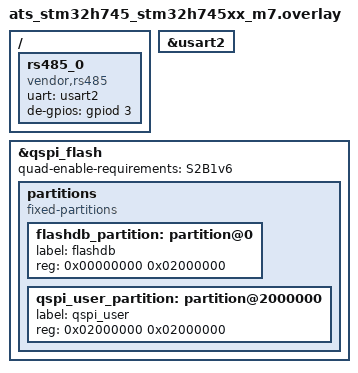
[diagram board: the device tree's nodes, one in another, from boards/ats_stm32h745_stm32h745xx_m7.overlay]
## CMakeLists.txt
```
#-------------------------------------------------------------------------------
# Zephyr Example Application
#
# Copyright (c) 2021 Nordic Semiconductor ASA
# SPDX-License-Identifier: Apache-2.0

cmake_minimum_required(VERSION 3.13.1)
find_package(Zephyr REQUIRED HINTS $ENV{ZEPHYR_BASE})

project(app LANGUAGES C)

target_include_directories(app PRIVATE
                src
                ../lib/FlashDB/inc)

target_sources(app PRIVATE
                src/main.c
                src/modbus_service.c
                src/usart_service.c
                src/modbus_points_db.c
                src/flashdb_port_zephyr.c
                src/fal_stub_zephyr.c
                ../lib/FlashDB/src/fdb.c
                ../lib/FlashDB/src/fdb_utils.c
                ../lib/FlashDB/src/fdb_kvdb.c)

# The code below locates the git index file for this repository and adds it as a dependency for
# the application VERSION file so that if the repo has a new commit added, even if no files in
# the build have changed, the application version file will be regenerated with the new git commit
find_package(Git QUIET)
if(GIT_FOUND)
  execute_process(
    COMMAND ${GIT_EXECUTABLE} rev-parse --absolute-git-dir
    WORKING_DIRECTORY .
    OUTPUT_VARIABLE application_git_dir
    OUTPUT_STRIP_TRAILING_WHITESPACE
    ERROR_STRIP_TRAILING_WHITESPACE
    ERROR_VARIABLE stderr
    RESULT_VARIABLE return_code
  )
  # If there is an error e.g. it is not a git repo, we just silently ignore it and continue
  # without a dependency, this will be the case with freestanding applications.
  if(NOT return_code)
    if(NOT "${stderr}" STREQUAL "")
      message(WARNING "Application build version git rev-parse warned: ${stderr}")
    endif()

    set_property(TARGET app_version_h PROPERTY APP_VERSION_DEPENDS ${application_git_dir}/index)
  endif()
endif()
```

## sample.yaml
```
# This file is provided so that the application can be compiled using Twister,
# the Zephyr testing tool. In this file, multiple combinations can be specified,
# so that you can easily test all of them locally or in CI.
sample:
  description: Example application
  name: example-application 
common:
  build_only: true
  integration_platforms:
    - ats_stm32h745
tests:
  app.default: {}
  app.debug:
    extra_overlay_confs:
      - debug.conf
```

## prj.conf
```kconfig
# Copyright (c) 2021 Nordic Semiconductor ASA
# SPDX-License-Identifier: Apache-2.0

# -------------------- Common --------------------
CONFIG_GPIO=y
CONFIG_SERIAL=y
CONFIG_PRINTK=y
CONFIG_LOG=y

# Enable debug during sleep/stop/standby modes
CONFIG_STM32_ENABLE_DEBUG_SLEEP_STOP=y

# -------------------- Flash / QSPI partition (for FlashDB port) --------------------
CONFIG_FLASH=y
CONFIG_FLASH_PAGE_LAYOUT=y
CONFIG_FLASH_MAP=y
CONFIG_FLASH_JESD216_API=y
CONFIG_FLASH_EX_OP_ENABLED=y
CONFIG_FLASH_STM32_QSPI_GENERIC_READ=y

# -------------------- Modbus (official Zephyr subsystem) --------------------
CONFIG_DMA=y
CONFIG_DMA_STM32=y
CONFIG_UART_ASYNC_API=y
CONFIG_UART_LINE_CTRL=n
CONFIG_NOCACHE_MEMORY=y
CONFIG_MODBUS=y
CONFIG_MODBUS_ROLE_SERVER=y
CONFIG_MODBUS_RAW_ADU=y
CONFIG_MODBUS_NUMOF_RAW_ADU=1

# Optional tuning
CONFIG_MAIN_STACK_SIZE=4096
```

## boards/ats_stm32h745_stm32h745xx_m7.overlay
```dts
/*
 * ATS-M7 app overlay
 * - Application-managed RS485 backend on USART2
 * - QSPI fixed partitions: first half reserved for FlashDB
 */

&usart2 {
	status = "okay";
};

/ {
	rs485_0: rs485_0 {
		compatible = "vendor,rs485";
		status = "okay";
		uart = <&usart2>;
		/* Adjust this pin to your actual RS485 DE wiring if different. */
		de-gpios = <&gpiod 3 GPIO_ACTIVE_HIGH>;
	};
};

&qspi_flash {
	/* Override SFDP QER value (7 unsupported by stm32-qspi driver path). */
	quad-enable-requirements = "S2B1v6";

	partitions {
		compatible = "fixed-partitions";
		#address-cells = <1>;
		#size-cells = <1>;

		/* 64MiB external flash first half for FlashDB */
		flashdb_partition: partition@0 {
			label = "flashdb";
			reg = <0x00000000 0x02000000>;
		};

		/* Remaining second half for future data/filesystem */
		qspi_user_partition: partition@2000000 {
			label = "qspi_user";
			reg = <0x02000000 0x02000000>;
		};
	};
};
```

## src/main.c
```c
#include <zephyr/kernel.h>
#include <zephyr/sys/printk.h>

#include "modbus_service.h"
#include "flashdb_port_zephyr.h"

/*
 * 应用主入口流程：
 * 1) 初始化 QSPI 分区访问层（供点位持久化使用）
 * 2) 初始化 Modbus RAW + 应用层 RS485 服务
 * 3) 高频执行 tick（驱动收包与心跳维护）
 */
int main(void)
{
	int ret;
	printk("flashdb_port_init start\n");
	ret = flashdb_port_init();
	if (ret != 0) {
		printk("flashdb_port_init failed: %d\n", ret);
		return 0;
	}

	ret = flashdb_port_print_jedec_id();
	if (ret != 0) {
		printk("flashdb_port_print_jedec_id failed: %d\n", ret);
	}

	ret = flashdb_port_print_sfdp_dw15();
	if (ret != 0) {
		printk("flashdb_port_print_sfdp_dw15 failed: %d\n", ret);
	}

	printk("flashdb_port_self_test start\n");
	ret = flashdb_port_self_test();
	if (ret != 0) {
		printk("flashdb_port_self_test failed: %d\n", ret);
		return 0;
	}

	ret = modbus_service_init();
	if (ret != 0) {
		printk("modbus_service_init failed: %d\n", ret);
		return 0;
	}

	while (1) {
		modbus_service_tick();
		k_sleep(K_MSEC(1));
	}

	return 0;
}
```

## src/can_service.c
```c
#include <zephyr/device.h>
#include <zephyr/devicetree.h>
#include <zephyr/drivers/can.h>
#include <zephyr/kernel.h>
#include <zephyr/sys/printk.h>
#include <zephyr/sys/util.h>

#include <errno.h>
#include <string.h>

#include "can_service.h"

/* 板级 DTS 中的 CAN 设备节点 */
#define CAN_NODE DT_NODELABEL(fdcan1)
#define CAN_RX_MSGQ_LEN 16
#define CAN_BITRATE DT_PROP_OR(CAN_NODE, bus_speed, 500000)
#define CAN_SEND_TIMEOUT K_MSEC(100)

static const struct device *can_dev = DEVICE_DT_GET(CAN_NODE);
CAN_MSGQ_DEFINE(can_rx_msgq, CAN_RX_MSGQ_LEN);

/* 当前已安装的标准/扩展过滤器 ID（用于后续移除） */
static int can_rx_filter_std_id = -1;
static int can_rx_filter_ext_id = -1;

static void can_remove_all_filters(void)
{
	if (can_rx_filter_std_id >= 0) {
		can_remove_rx_filter(can_dev, can_rx_filter_std_id);
		can_rx_filter_std_id = -1;
	}

	if (can_rx_filter_ext_id >= 0) {
		can_remove_rx_filter(can_dev, can_rx_filter_ext_id);
		can_rx_filter_ext_id = -1;
	}
}

/* 安装“全接收”过滤器：标准帧+扩展帧都放进消息队列 */
static int can_service_set_rx_filter_all(void)
{
	struct can_filter std_all = {
		.id = 0U,
		.mask = 0U,
		.flags = 0U,
	};
	struct can_filter ext_all = {
		.id = 0U,
		.mask = 0U,
		.flags = CAN_FILTER_IDE,
	};
	int ret;
	int ext_ret;

	can_remove_all_filters();
	k_msgq_purge(&can_rx_msgq);

	ret = can_add_rx_filter_msgq(can_dev, &can_rx_msgq, &std_all);
	if (ret < 0) {
		return ret;
	}
	can_rx_filter_std_id = ret;

	ext_ret = can_add_rx_filter_msgq(can_dev, &can_rx_msgq, &ext_all);
	if (ext_ret >= 0) {
		can_rx_filter_ext_id = ext_ret;
		printk("CAN RX filter: all standard + all extended\n");
	} else {
		/* 部分硬件场景可能不支持扩展过滤器，但标准帧仍可工作 */
		printk("CAN RX filter: all standard (extended add failed: %d)\n", ext_ret);
	}

	return 0;
}

/* 状态枚举转文本，便于日志观察 */
static const char *can_state_name(enum can_state state)
{
	switch (state) {
	case CAN_STATE_ERROR_ACTIVE:
		return "error-active";
	case CAN_STATE_ERROR_WARNING:
		return "error-warning";
	case CAN_STATE_ERROR_PASSIVE:
		return "error-passive";
	case CAN_STATE_BUS_OFF:
		return "bus-off";
	case CAN_STATE_STOPPED:
		return "stopped";
	default:
		return "unknown";
	}
}

/* CAN 总线状态变化回调 */
static void can_state_change_cb(const struct device *dev, enum can_state state,
				struct can_bus_err_cnt err_cnt, void *user_data)
{
	ARG_UNUSED(dev);
	ARG_UNUSED(user_data);

	printk("CAN state=%s tx_err=%u rx_err=%u\n",
	       can_state_name(state), err_cnt.tx_err_cnt, err_cnt.rx_err_cnt);
}

/* 统一发送入口：根据 flags 判定标准帧/扩展帧 */
static int can_service_send_internal(uint32_t id, uint8_t flags,
				     const uint8_t *data, size_t len)
{
	struct can_frame frame = {0};

	if ((data == NULL) && (len > 0U)) {
		return -EINVAL;
	}

	if (len > CAN_MAX_DLC) {
		return -EINVAL;
	}

	if ((flags & CAN_FRAME_IDE) != 0U) {
		if (id > CAN_EXT_ID_MASK) {
			return -EINVAL;
		}
	} else {
		if (id > CAN_STD_ID_MASK) {
			return -EINVAL;
		}
	}

	frame.id = id;
	frame.flags = flags;
	frame.dlc = can_bytes_to_dlc((uint8_t)len);

	if (len > 0U) {
		memcpy(frame.data, data, len);
	}

	return can_send(can_dev, &frame, CAN_SEND_TIMEOUT, NULL, NULL);
}

int can_service_init(void)
{
	int ret;
	uint32_t core_clk = 0U;

	if (!device_is_ready(can_dev)) {
		printk("CAN not ready\n");
		return -ENODEV;
	}

	can_set_state_change_callback(can_dev, can_state_change_cb, NULL);

	/* 先停再配，避免重复初始化导致状态不一致 */
	ret = can_stop(can_dev);
	if ((ret != 0) && (ret != -EALREADY)) {
		printk("CAN stop failed: %d\n", ret);
		return ret;
	}

	ret = can_set_mode(can_dev, CAN_MODE_NORMAL);
	if (ret != 0) {
		printk("CAN set mode failed: %d\n", ret);
		return ret;
	}

	ret = can_set_bitrate(can_dev, CAN_BITRATE);
	if (ret != 0) {
		printk("CAN set bitrate failed: %d\n", ret);
		return ret;
	}

	ret = can_service_set_rx_filter_all();
	if (ret != 0) {
		printk("CAN set filter failed: %d\n", ret);
		return ret;
	}

	ret = can_start(can_dev);
	if (ret != 0) {
		printk("CAN start failed: %d\n", ret);
		return ret;
	}

	ret = can_get_core_clock(can_dev, &core_clk);
	if (ret == 0) {
		printk("CAN init OK dev=%s bitrate=%u core_clk=%u\n",
		       can_dev->name, CAN_BITRATE, core_clk);
	} else {
		printk("CAN init OK dev=%s bitrate=%u core_clk=n/a (ret=%d)\n",
		       can_dev->name, CAN_BITRATE, ret);
	}

	return 0;
}

int can_service_set_rx_filter(uint32_t id, uint32_t mask, uint8_t flags)
{
	struct can_filter filter = {
		.id = id,
		.mask = mask,
		.flags = flags,
	};
	int filter_id;

	/* 参数合法性校验：标准帧/扩展帧 ID 范围不同 */
	if ((flags & CAN_FILTER_IDE) != 0U) {
		if ((id > CAN_EXT_ID_MASK) || (mask > CAN_EXT_ID_MASK)) {
			return -EINVAL;
		}
	} else {
		if ((id > CAN_STD_ID_MASK) || (mask > CAN_STD_ID_MASK)) {
			return -EINVAL;
		}
	}

	can_remove_all_filters();
	k_msgq_purge(&can_rx_msgq);

	filter_id = can_add_rx_filter_msgq(can_dev, &can_rx_msgq, &filter);
	if (filter_id < 0) {
		return filter_id;
	}

	if ((flags & CAN_FILTER_IDE) != 0U) {
		can_rx_filter_ext_id = filter_id;
	} else {
		can_rx_filter_std_id = filter_id;
	}

	return 0;
}

int can_service_send(uint32_t id, const uint8_t *data, size_t len)
{
	return can_service_send_internal(id, 0, data, len);
}

int can_service_send_ext(uint32_t id, const uint8_t *data, size_t len)
{
	return can_service_send_internal(id, CAN_FRAME_IDE, data, len);
}

int can_service_read(struct can_frame *frame, k_timeout_t timeout)
{
	if (frame == NULL) {
		return -EINVAL;
	}

	return k_msgq_get(&can_rx_msgq, frame, timeout);
}
```

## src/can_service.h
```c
#ifndef CAN_SERVICE_H
#define CAN_SERVICE_H

#include <stddef.h>
#include <stdint.h>

#include <zephyr/drivers/can.h>
#include <zephyr/kernel.h>

/* 初始化 CAN 控制器（模式、波特率、过滤器、启动） */
int can_service_init(void);

/* 设置接收过滤器（id/mask/标准帧或扩展帧） */
int can_service_set_rx_filter(uint32_t id, uint32_t mask, uint8_t flags);

/* 发送标准帧 */
int can_service_send(uint32_t id, const uint8_t *data, size_t len);

/* 发送扩展帧 */
int can_service_send_ext(uint32_t id, const uint8_t *data, size_t len);

/* 从接收消息队列读取一帧 */
int can_service_read(struct can_frame *frame, k_timeout_t timeout);

#endif /* CAN_SERVICE_H */
```

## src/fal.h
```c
#ifndef ATS_FAL_H
#define ATS_FAL_H

#include <stdint.h>
#include <stddef.h>

/* 与 FlashDB/FAL 保持一致的设备名长度 */
#ifndef FAL_DEV_NAME_MAX
#define FAL_DEV_NAME_MAX 24
#endif

/* 简化版 flash 设备结构，仅保留 FlashDB 会用到的字段 */
struct fal_flash_dev {
	char name[FAL_DEV_NAME_MAX];
	uint32_t addr;
	size_t len;
	size_t blk_size;
	struct {
		int (*init)(void);
		int (*read)(long offset, uint8_t *buf, size_t size);
		int (*write)(long offset, const uint8_t *buf, size_t size);
		int (*erase)(long offset, size_t size);
	} ops;
	size_t write_gran;
};

/* 简化版分区结构，满足 FlashDB KVDB 的依赖 */
struct fal_partition {
	uint32_t magic_word;
	char name[FAL_DEV_NAME_MAX];
	char flash_name[FAL_DEV_NAME_MAX];
	long offset;
	size_t len;
	uint32_t reserved;
};

int fal_init(void);
const struct fal_flash_dev *fal_flash_device_find(const char *name);
const struct fal_partition *fal_partition_find(const char *name);
const struct fal_partition *fal_get_partition_table(size_t *len);
void fal_set_partition_table_temp(struct fal_partition *table, size_t len);
int fal_partition_read(const struct fal_partition *part, uint32_t addr, uint8_t *buf, size_t size);
int fal_partition_write(const struct fal_partition *part, uint32_t addr, const uint8_t *buf, size_t size);
int fal_partition_erase(const struct fal_partition *part, uint32_t addr, size_t size);
int fal_partition_erase_all(const struct fal_partition *part);
void fal_show_part_table(void);

#endif /* ATS_FAL_H */
```

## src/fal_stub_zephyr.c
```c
#include <zephyr/sys/printk.h>
#include <zephyr/sys/util.h>
#include <string.h>
#include <stdbool.h>

#include "fal.h"
#include "flashdb_port_zephyr.h"

/* FlashDB 初始化路径使用 "flashdb"，需与这里分区名一致 */
#define ATS_FAL_FLASH_NAME     "zephyr_qspi"
#define ATS_FAL_PART_NAME      "flashdb"
#define ATS_FAL_PART_MAGIC     0x45504641u /* "AFPE" */

static struct fal_flash_dev g_flash_dev;
static struct fal_partition g_partition;
static bool g_fal_inited;

static void copy_name(char *dst, size_t dst_size, const char *src)
{
	if (dst_size == 0U) {
		return;
	}

	strncpy(dst, src, dst_size - 1U);
	dst[dst_size - 1U] = '\0';
}

static bool part_is_valid(const struct fal_partition *part)
{
	return (part == &g_partition) && g_fal_inited;
}

int fal_init(void)
{
	int ret;
	size_t area_size;
	size_t erase_size;

	if (g_fal_inited) {
		return 1;
	}

	/* main.c 已初始化过时，这里可复用；未初始化时再补一次 */
	if (flashdb_port_size() == 0U) {
		ret = flashdb_port_init();
		if (ret != 0) {
			printk("fal_init: flashdb_port_init failed: %d\n", ret);
			return -1;
		}
	}

	area_size = flashdb_port_size();
	erase_size = flashdb_port_erase_size();
	if (area_size == 0U || erase_size == 0U) {
		printk("fal_init: invalid flashdb area size=%zu erase=%zu\n", area_size, erase_size);
		return -1;
	}

	memset(&g_flash_dev, 0, sizeof(g_flash_dev));
	copy_name(g_flash_dev.name, sizeof(g_flash_dev.name), ATS_FAL_FLASH_NAME);
	g_flash_dev.addr = 0U;
	g_flash_dev.len = area_size;
	g_flash_dev.blk_size = erase_size;
	g_flash_dev.write_gran = 1U;

	memset(&g_partition, 0, sizeof(g_partition));
	g_partition.magic_word = ATS_FAL_PART_MAGIC;
	copy_name(g_partition.name, sizeof(g_partition.name), ATS_FAL_PART_NAME);
	copy_name(g_partition.flash_name, sizeof(g_partition.flash_name), ATS_FAL_FLASH_NAME);
	g_partition.offset = 0;
	g_partition.len = area_size;
	g_partition.reserved = 0U;

	g_fal_inited = true;
	return 1;
}

const struct fal_flash_dev *fal_flash_device_find(const char *name)
{
	if (name == NULL) {
		return NULL;
	}

	if (!g_fal_inited && fal_init() < 0) {
		return NULL;
	}

	if (strcmp(name, g_flash_dev.name) == 0) {
		return &g_flash_dev;
	}

	return NULL;
}

const struct fal_partition *fal_partition_find(const char *name)
{
	if (name == NULL) {
		return NULL;
	}

	if (!g_fal_inited && fal_init() < 0) {
		return NULL;
	}

	if (strcmp(name, g_partition.name) == 0) {
		return &g_partition;
	}

	return NULL;
}

const struct fal_partition *fal_get_partition_table(size_t *len)
{
	if (!g_fal_inited && fal_init() < 0) {
		if (len != NULL) {
			*len = 0U;
		}
		return NULL;
	}

	if (len != NULL) {
		*len = 1U;
	}

	return &g_partition;
}

void fal_set_partition_table_temp(struct fal_partition *table, size_t len)
{
	ARG_UNUSED(table);
	ARG_UNUSED(len);
	/* 该简化适配层不支持运行时替换分区表 */
}

int fal_partition_read(const struct fal_partition *part, uint32_t addr, uint8_t *buf, size_t size)
{
	int ret;

	if (!part_is_valid(part) || buf == NULL) {
		return -1;
	}
	if ((size_t)addr > part->len || size > (part->len - (size_t)addr)) {
		return -1;
	}

	ret = flashdb_port_read((off_t)addr, buf, size);
	return (ret == 0) ? (int)size : -1;
}

int fal_partition_write(const struct fal_partition *part, uint32_t addr, const uint8_t *buf, size_t size)
{
	int ret;

	if (!part_is_valid(part) || buf == NULL) {
		return -1;
	}
	if ((size_t)addr > part->len || size > (part->len - (size_t)addr)) {
		return -1;
	}

	ret = flashdb_port_write((off_t)addr, buf, size);
	return (ret == 0) ? (int)size : -1;
}

int fal_partition_erase(const struct fal_partition *part, uint32_t addr, size_t size)
{
	int ret;

	if (!part_is_valid(part)) {
		return -1;
	}
	if ((size_t)addr > part->len || size > (part->len - (size_t)addr)) {
		return -1;
	}

	ret = flashdb_port_erase((off_t)addr, size);
	return (ret == 0) ? (int)size : -1;
}

int fal_partition_erase_all(const struct fal_partition *part)
{
	if (!part_is_valid(part)) {
		return -1;
	}

	return fal_partition_erase(part, 0U, part->len);
}

void fal_show_part_table(void)
{
	if (!g_fal_inited && fal_init() < 0) {
		printk("fal_show_part_table: not initialized\n");
		return;
	}

	printk("FAL partition: name=%s flash=%s offset=0x%lx len=0x%zx blk=0x%zx\n",
	       g_partition.name, g_partition.flash_name,
	       (unsigned long)g_partition.offset, g_partition.len, g_flash_dev.blk_size);
}
```

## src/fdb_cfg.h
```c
#ifndef FDB_CFG_H
#define FDB_CFG_H

#include <zephyr/sys/printk.h>

/* 仅启用 KVDB，满足 Modbus 点位持久化需求 */
#define FDB_USING_KVDB

/* 使用 FAL 模式，将 FlashDB 底层映射到 Zephyr QSPI 分区 */
#define FDB_USING_FAL_MODE

/*
 * 写粒度单位是 bit。
 * QSPI NOR Flash 对应 1 bit（可从 1 写成 0）。
 */
#define FDB_WRITE_GRAN 1

/* FlashDB 日志重定向到 Zephyr 控制台 */
#define FDB_PRINT(...) printk(__VA_ARGS__)

#endif /* FDB_CFG_H */
```

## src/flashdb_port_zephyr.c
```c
#include <zephyr/kernel.h>
#include <zephyr/storage/flash_map.h>
#include <zephyr/drivers/flash.h>
#include <zephyr/drivers/flash/stm32_flash_api_extensions.h>
#include <zephyr/sys/printk.h>
#include <zephyr/sys/util.h>
#include <soc.h>
#include <errno.h>
#include <stdint.h>
#include <string.h>

#include "flashdb_port_zephyr.h"

/* 对应 overlay 中定义的 qspi 前半区分区 */
#define FLASHDB_PARTITION_NODE DT_NODELABEL(flashdb_partition)
BUILD_ASSERT(DT_NODE_HAS_STATUS(FLASHDB_PARTITION_NODE, okay),
	"flashdb_partition is missing or disabled");

/* Zephyr flash_map 分区 ID */
#define FLASHDB_AREA_ID PARTITION_ID(flashdb_partition)
#define FLASH_CMD_RDID_9F 0x9FU
#define FLASH_CMD_RDID_9E 0x9EU
#define FLASH_CMD_READ_SFDP 0x5AU
#define SFDP_MAGIC_LE 0x50444653UL

static const struct flash_area *flashdb_area;
static size_t flashdb_erase_size;
static size_t flashdb_write_align;

#if defined(CONFIG_FLASH_EX_OP_ENABLED) && defined(CONFIG_FLASH_STM32_QSPI_GENERIC_READ)
static int qspi_read_id_raw(const struct device *dev,
			    uint8_t opcode,
			    uint32_t instr_mode,
			    uint32_t data_mode,
			    uint8_t *out,
			    size_t out_len)
{
	QSPI_CommandTypeDef cmd = {
		.Instruction = opcode,
		.AddressSize = QSPI_ADDRESS_NONE,
		.AddressMode = QSPI_ADDRESS_NONE,
		.DummyCycles = 0U,
		.InstructionMode = instr_mode,
		.DataMode = data_mode,
		.NbData = out_len,
	};

	return flash_ex_op(dev, FLASH_STM32_QSPI_EX_OP_GENERIC_READ,
			   (uintptr_t)&cmd, out);
}

static int qspi_read_sfdp_raw_custom(const struct device *dev,
				     uint32_t addr,
				     uint8_t dummy_cycles,
				     uint32_t addr_size,
				     uint8_t *out,
				     size_t out_len)
{
	QSPI_CommandTypeDef cmd = {
		.Instruction = FLASH_CMD_READ_SFDP,
		.Address = addr,
		.AddressSize = addr_size,
		.AddressMode = QSPI_ADDRESS_1_LINE,
		.DummyCycles = dummy_cycles,
		.InstructionMode = QSPI_INSTRUCTION_1_LINE,
		.DataMode = QSPI_DATA_1_LINE,
		.NbData = out_len,
	};

	return flash_ex_op(dev, FLASH_STM32_QSPI_EX_OP_GENERIC_READ,
			   (uintptr_t)&cmd, out);
}

static int qspi_read_sfdp_raw(const struct device *dev,
			      uint32_t addr,
			      uint8_t *out,
			      size_t out_len)
{
	return qspi_read_sfdp_raw_custom(dev, addr, 8U, QSPI_ADDRESS_24_BITS, out, out_len);
}
#endif

static uint32_t u32_from_le_bytes(const uint8_t *p)
{
	return ((uint32_t)p[0]) |
	       ((uint32_t)p[1] << 8) |
	       ((uint32_t)p[2] << 16) |
	       ((uint32_t)p[3] << 24);
}

/* 越界保护：所有读写擦都先经过该检查 */
static int flashdb_check_range(off_t off, size_t len)
{
	if (flashdb_area == NULL) {
		return -EACCES;
	}

	if (off < 0 || (size_t)off > flashdb_area->fa_size ||
	    len > (flashdb_area->fa_size - (size_t)off)) {
		return -EINVAL;
	}

	return 0;
}

int flashdb_port_init(void)
{
	struct flash_pages_info page;
	int ret;

	ret = flash_area_open(FLASHDB_AREA_ID, &flashdb_area);
	if (ret != 0) {
		printk("flash_area_open(flashdb) failed: %d\n", ret);
		return ret;
	}

	if (!flash_area_device_is_ready(flashdb_area)) {
		printk("flashdb flash device not ready\n");
		return -ENODEV;
	}

	/* 根据分区起始偏移查询擦除页大小 */
	ret = flash_get_page_info_by_offs(flashdb_area->fa_dev,
					  flashdb_area->fa_off, &page);
	if (ret != 0) {
		printk("flash_get_page_info_by_offs failed: %d\n", ret);
		return ret;
	}

	flashdb_erase_size = page.size;
	flashdb_write_align = flash_area_align(flashdb_area);
	if (flashdb_write_align == 0U) {
		flashdb_write_align = 1U;
	}

	printk("FlashDB area ready: id=%u off=0x%lx size=0x%zx erase=0x%zx align=%zu\n",
		FLASHDB_AREA_ID,
		(unsigned long)flashdb_area->fa_off,
		flashdb_area->fa_size,
		flashdb_erase_size,
		flashdb_write_align);

	return 0;
}

size_t flashdb_port_size(void)
{
	return flashdb_area ? flashdb_area->fa_size : 0U;
}

size_t flashdb_port_align(void)
{
	return flashdb_write_align;
}

size_t flashdb_port_erase_size(void)
{
	return flashdb_erase_size;
}

int flashdb_port_read(off_t off, void *buf, size_t len)
{
	int ret = flashdb_check_range(off, len);

	if (ret != 0) {
		return ret;
	}

	return flash_area_read(flashdb_area, off, buf, len);
}

int flashdb_port_write(off_t off, const void *buf, size_t len)
{
	int ret = flashdb_check_range(off, len);

	if (ret != 0) {
		return ret;
	}

	return flash_area_write(flashdb_area, off, buf, len);
}

int flashdb_port_erase(off_t off, size_t len)
{
	int ret = flashdb_check_range(off, len);

	if (ret != 0) {
		return ret;
	}

	return flash_area_erase(flashdb_area, off, len);
}

int flashdb_port_self_test(void)
{
	uint8_t tx[64];
	uint8_t rx[64];
	const char msg[] = "flashdb-qspi-test";
	size_t align;
	size_t wr_len;
	int ret;

	if (flashdb_area == NULL) {
		return -EACCES;
	}

	align = flash_area_align(flashdb_area);
	if (align == 0U) {
		align = 1U;
	}

	/* flash 写入长度必须满足对齐约束 */
	wr_len = ROUND_UP(sizeof(msg), align);
	if (wr_len > sizeof(tx)) {
		return -ENOMEM;
	}

	memset(tx, 0xFF, sizeof(tx));
	memcpy(tx, msg, sizeof(msg));
	memset(rx, 0, sizeof(rx));

	ret = flashdb_port_erase(0, flashdb_erase_size);
	if (ret != 0) {
		printk("flashdb erase failed: %d\n", ret);
		return ret;
	}

	ret = flashdb_port_write(0, tx, wr_len);
	if (ret != 0) {
		printk("flashdb write failed: %d\n", ret);
		return ret;
	}

	ret = flashdb_port_read(0, rx, wr_len);
	if (ret != 0) {
		printk("flashdb read failed: %d\n", ret);
		return ret;
	}

	if (memcmp(tx, rx, wr_len) != 0) {
		printk("flashdb verify failed\n");
		return -EIO;
	}

	printk("FlashDB partition smoke test passed\n");
	return 0;
}

int flashdb_port_print_jedec_id(void)
{
	if (flashdb_area == NULL) {
		return -EACCES;
	}

#if defined(CONFIG_FLASH_EX_OP_ENABLED) && defined(CONFIG_FLASH_STM32_QSPI_GENERIC_READ)
	uint8_t id_spi_9f[4] = { 0 };
	uint8_t id_spi_9e[4] = { 0 };
	int ret_9f;
	int ret_spi_9e;

	ret_9f = qspi_read_id_raw(flashdb_area->fa_dev,
				  FLASH_CMD_RDID_9F,
				  QSPI_INSTRUCTION_1_LINE,
				  QSPI_DATA_1_LINE,
				  id_spi_9f, sizeof(id_spi_9f));
	ret_spi_9e = qspi_read_id_raw(flashdb_area->fa_dev,
				      FLASH_CMD_RDID_9E,
				      QSPI_INSTRUCTION_1_LINE,
				      QSPI_DATA_1_LINE,
				      id_spi_9e, sizeof(id_spi_9e));

	if (ret_9f == 0) {
		printk("RDID QSPI(1-1-1) 0x9F: %02x %02x %02x %02x\n",
		       id_spi_9f[0], id_spi_9f[1], id_spi_9f[2], id_spi_9f[3]);
		printk("RDID 0x9F decode: MID=%02x TYPE=%02x CAP=%02x DID3=%02x\n",
		       id_spi_9f[0], id_spi_9f[1], id_spi_9f[2], id_spi_9f[3]);
	} else {
		printk("RDID QSPI(1-1-1) 0x9F read failed: %d\n", ret_9f);
	}

	if (ret_spi_9e == 0) {
		printk("RDID QSPI(1-1-1) 0x9E: %02x %02x %02x %02x\n",
		       id_spi_9e[0], id_spi_9e[1], id_spi_9e[2], id_spi_9e[3]);
	} else {
		printk("RDID QSPI(1-1-1) 0x9E read failed: %d\n", ret_spi_9e);
	}

	if ((ret_9f == 0) || (ret_spi_9e == 0)) {
		return 0;
	}

	printk("raw RDID reads all failed\n");
#endif

#if defined(CONFIG_FLASH_JESD216_API)
	{
		uint8_t id[3] = { 0 };
		int ret;

		ret = flash_read_jedec_id(flashdb_area->fa_dev, id);
		if (ret != 0) {
			printk("flash_read_jedec_id failed: %d\n", ret);
			return ret;
		}

		printk("QSPI JEDEC ID (fallback, 3B): %02x %02x %02x\n",
		       id[0], id[1], id[2]);
		return 0;
	}
#else
	printk("flash_read_jedec_id unavailable: CONFIG_FLASH_JESD216_API is disabled\n");
	return -ENOTSUP;
#endif
}

int flashdb_port_print_sfdp_dw15(void)
{
	if (flashdb_area == NULL) {
		return -EACCES;
	}

#if defined(CONFIG_FLASH_EX_OP_ENABLED) && defined(CONFIG_FLASH_STM32_QSPI_GENERIC_READ)
	uint8_t sfdp_hdr[64] = { 0 };
	uint8_t bfp[80] = { 0 };
	uint32_t magic;
	uint32_t bfp_addr = 0U;
	size_t bfp_len_dw = 0U;
	uint8_t nph;
	size_t ph_count;
	size_t i;
	int ret;

	/* Manual-compatible mode: 5Ah + 24-bit address + 8 dummy + 1-1-1 lines */
	ret = qspi_read_sfdp_raw(flashdb_area->fa_dev, 0U, sfdp_hdr, sizeof(sfdp_hdr));
	if (ret != 0) {
		printk("SFDP raw read failed at 0x000000: %d\n", ret);
		return ret;
	}

	magic = u32_from_le_bytes(&sfdp_hdr[0]);
	nph = sfdp_hdr[6];
	ph_count = (size_t)nph + 1U;
	printk("SFDP header: magic=%02x %02x %02x %02x (0x%08lx) rev=%u.%u nph=%u access=0x%02x\n",
	       sfdp_hdr[0], sfdp_hdr[1], sfdp_hdr[2], sfdp_hdr[3], (unsigned long)magic,
	       sfdp_hdr[5], sfdp_hdr[4], nph, sfdp_hdr[7]);
	if (magic != SFDP_MAGIC_LE) {
		printk("SFDP magic mismatch\n");
		return -EINVAL;
	}

	for (i = 0; i < ph_count; i++) {
		size_t off = 8U + (i * 8U);
		uint16_t id;
		uint8_t len_dw;
		uint32_t addr;

		if ((off + 7U) >= sizeof(sfdp_hdr)) {
			printk("SFDP PH truncated at index %zu\n", i);
			break;
		}

		id = ((uint16_t)sfdp_hdr[off + 7U] << 8) | sfdp_hdr[off + 0U];
		len_dw = sfdp_hdr[off + 3U];
		addr = ((uint32_t)sfdp_hdr[off + 4U]) |
		       ((uint32_t)sfdp_hdr[off + 5U] << 8) |
		       ((uint32_t)sfdp_hdr[off + 6U] << 16);
		printk("SFDP PH%zu: id=%04x len_dw=%u addr=0x%06lx rev=%u.%u\n",
		       i, id, len_dw, (unsigned long)addr, sfdp_hdr[off + 2U], sfdp_hdr[off + 1U]);

		/* Basic Flash Parameter table (BFP) */
		if ((id == 0xFF00U) && (bfp_len_dw == 0U)) {
			bfp_addr = addr;
			bfp_len_dw = len_dw;
		}
	}

	if (bfp_len_dw < 15U) {
		printk("BFP length too short for DW15: %zu DW\n", bfp_len_dw);
		return -ENOTSUP;
	}

	ret = qspi_read_sfdp_raw(flashdb_area->fa_dev, bfp_addr, bfp, sizeof(bfp));
	if (ret != 0) {
		printk("BFP raw read failed at 0x%06lx: %d\n", (unsigned long)bfp_addr, ret);
		return ret;
	}

	{
		const size_t dw15_off = (15U - 1U) * 4U;
		uint32_t dw15 = u32_from_le_bytes(&bfp[dw15_off]);
		uint32_t qer = (dw15 >> 20) & 0x7U;
		printk("BFP DW15 @0x%06lx: %02x %02x %02x %02x (LE32=0x%08lx QER=%lu)\n",
		       (unsigned long)(bfp_addr + dw15_off),
		       bfp[dw15_off + 0U], bfp[dw15_off + 1U], bfp[dw15_off + 2U], bfp[dw15_off + 3U],
		       (unsigned long)dw15, (unsigned long)qer);
	}

	return 0;
#else
	printk("SFDP raw read unavailable: need CONFIG_FLASH_EX_OP_ENABLED + CONFIG_FLASH_STM32_QSPI_GENERIC_READ\n");
	return -ENOTSUP;
#endif
}
```

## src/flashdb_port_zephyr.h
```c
#ifndef FLASHDB_PORT_ZEPHYR_H
#define FLASHDB_PORT_ZEPHYR_H

#include <stddef.h>
#include <sys/types.h>

/* 初始化 flashdb_partition 访问句柄与页参数 */
int flashdb_port_init(void);

/* 获取分区总大小 */
size_t flashdb_port_size(void);

/* 获取写对齐要求（字节） */
size_t flashdb_port_align(void);

/* 获取擦除粒度（页/扇区大小） */
size_t flashdb_port_erase_size(void);

/* 从分区内偏移读取数据 */
int flashdb_port_read(off_t off, void *buf, size_t len);

/* 向分区内偏移写入数据 */
int flashdb_port_write(off_t off, const void *buf, size_t len);

/* 擦除分区内偏移范围 */
int flashdb_port_erase(off_t off, size_t len);

/* 冒烟测试：erase->write->read->verify（会改写分区起始区域） */
int flashdb_port_self_test(void);

/* 打印原始 RDID（QSPI 控制器 1-1-1 模式下的 0x9F/0x9E），失败时回退 3 字节 JEDEC API */
int flashdb_port_print_jedec_id(void);

/* 打印 SFDP 头、参数头与 BFP DW15（包含 QER 位提取） */
int flashdb_port_print_sfdp_dw15(void);

#endif /* FLASHDB_PORT_ZEPHYR_H */
```

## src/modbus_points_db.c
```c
#include <zephyr/kernel.h>
#include <zephyr/sys/util.h>
#include <zephyr/sys/printk.h>
#include <errno.h>
#include <stdbool.h>
#include <stdint.h>

#include <flashdb.h>

#include "modbus_points_db.h"

/* KVDB 实例：用于保存 Modbus Holding/Coil 点位 */
static struct fdb_kvdb g_modbus_kvdb;
/* FlashDB 内部回调的互斥锁 */
static struct k_mutex g_db_lock;
static bool g_db_ready;

/* 点位与 KV 键名映射（地址不变，键名可读） */
static char g_key_hr0[] = "hr0";
static char g_key_hr1[] = "hr1";
static char g_key_hr2[] = "hr2";
static char g_key_hr3[] = "hr3";
static char g_key_coil0[] = "coil0";
static char g_key_coil1[] = "coil1";

static char *const g_holding_keys[MODBUS_POINT_HR_COUNT] = {
	g_key_hr0, g_key_hr1, g_key_hr2, g_key_hr3
};

static char *const g_coil_keys[MODBUS_POINT_COIL_COUNT] = {
	g_key_coil0, g_key_coil1
};

/* 默认值：首次格式化或数据缺失时写入 */
static uint16_t g_default_hr0 = 1u;
static uint16_t g_default_hr1 = 100u;
static uint16_t g_default_hr2 = 500u;
static uint16_t g_default_hr3 = 0x1234u;
static uint8_t g_default_coil0 = 1u;
static uint8_t g_default_coil1 = 0u;

static struct fdb_default_kv_node g_default_nodes[] = {
	{ .key = g_key_hr0, .value = &g_default_hr0, .value_len = sizeof(g_default_hr0) },
	{ .key = g_key_hr1, .value = &g_default_hr1, .value_len = sizeof(g_default_hr1) },
	{ .key = g_key_hr2, .value = &g_default_hr2, .value_len = sizeof(g_default_hr2) },
	{ .key = g_key_hr3, .value = &g_default_hr3, .value_len = sizeof(g_default_hr3) },
	{ .key = g_key_coil0, .value = &g_default_coil0, .value_len = sizeof(g_default_coil0) },
	{ .key = g_key_coil1, .value = &g_default_coil1, .value_len = sizeof(g_default_coil1) },
};

static struct fdb_default_kv g_default_kv = {
	.kvs = g_default_nodes,
	.num = ARRAY_SIZE(g_default_nodes),
};

static void kvdb_lock(fdb_db_t db)
{
	ARG_UNUSED(db);
	k_mutex_lock(&g_db_lock, K_FOREVER);
}

static void kvdb_unlock(fdb_db_t db)
{
	ARG_UNUSED(db);
	k_mutex_unlock(&g_db_lock);
}

static int fdb_to_errno(fdb_err_t err)
{
	switch (err) {
	case FDB_NO_ERR:
		return 0;
	case FDB_PART_NOT_FOUND:
		return -ENOENT;
	case FDB_SAVED_FULL:
		return -ENOSPC;
	case FDB_ERASE_ERR:
	case FDB_READ_ERR:
	case FDB_WRITE_ERR:
		return -EIO;
	case FDB_KV_NAME_ERR:
	case FDB_KV_NAME_EXIST:
		return -EINVAL;
	case FDB_INIT_FAILED:
	default:
		return -EFAULT;
	}
}

int modbus_points_db_init(void)
{
	fdb_err_t ret;

	if (g_db_ready) {
		return 0;
	}

	k_mutex_init(&g_db_lock);

	/* 设置 FlashDB 内部锁，保证多上下文访问安全 */
	fdb_kvdb_control(&g_modbus_kvdb, FDB_KVDB_CTRL_SET_LOCK, (void *)kvdb_lock);
	fdb_kvdb_control(&g_modbus_kvdb, FDB_KVDB_CTRL_SET_UNLOCK, (void *)kvdb_unlock);

	/*
	 * path 使用 "flashdb"，对应 FAL 分区名（由 fal_stub_zephyr.c 提供）。
	 * 初始化后，默认 KV 会自动落盘。
	 */
	ret = fdb_kvdb_init(&g_modbus_kvdb, "modbus", "flashdb", &g_default_kv, NULL);
	if (ret != FDB_NO_ERR) {
		printk("fdb_kvdb_init failed: %d\n", (int)ret);
		return fdb_to_errno(ret);
	}

	g_db_ready = true;
	return 0;
}

int modbus_points_db_get_holding(uint16_t addr, uint16_t *value)
{
	struct fdb_blob blob;
	size_t rd_len;
	uint16_t tmp = 0u;

	if (!g_db_ready) {
		return -EACCES;
	}
	if (value == NULL) {
		return -EINVAL;
	}
	if (addr >= MODBUS_POINT_HR_COUNT) {
		return -ENOTSUP;
	}

	rd_len = fdb_kv_get_blob(&g_modbus_kvdb, g_holding_keys[addr],
				 fdb_blob_make(&blob, &tmp, sizeof(tmp)));
	if (rd_len != sizeof(tmp)) {
		return -ENOENT;
	}

	*value = tmp;
	return 0;
}

int modbus_points_db_set_holding(uint16_t addr, uint16_t value)
{
	struct fdb_blob blob;
	fdb_err_t ret;

	if (!g_db_ready) {
		return -EACCES;
	}
	if (addr >= MODBUS_POINT_HR_COUNT) {
		return -ENOTSUP;
	}

	ret = fdb_kv_set_blob(&g_modbus_kvdb, g_holding_keys[addr],
			      fdb_blob_make(&blob, &value, sizeof(value)));
	return fdb_to_errno(ret);
}

int modbus_points_db_get_coil(uint16_t addr, bool *state)
{
	struct fdb_blob blob;
	size_t rd_len;
	uint8_t tmp = 0u;

	if (!g_db_ready) {
		return -EACCES;
	}
	if (state == NULL) {
		return -EINVAL;
	}
	if (addr >= MODBUS_POINT_COIL_COUNT) {
		return -ENOTSUP;
	}

	rd_len = fdb_kv_get_blob(&g_modbus_kvdb, g_coil_keys[addr],
				 fdb_blob_make(&blob, &tmp, sizeof(tmp)));
	if (rd_len != sizeof(tmp)) {
		return -ENOENT;
	}

	*state = (tmp != 0u);
	return 0;
}

int modbus_points_db_set_coil(uint16_t addr, bool state)
{
	struct fdb_blob blob;
	fdb_err_t ret;
	uint8_t value = state ? 1u : 0u;

	if (!g_db_ready) {
		return -EACCES;
	}
	if (addr >= MODBUS_POINT_COIL_COUNT) {
		return -ENOTSUP;
	}

	ret = fdb_kv_set_blob(&g_modbus_kvdb, g_coil_keys[addr],
			      fdb_blob_make(&blob, &value, sizeof(value)));
	return fdb_to_errno(ret);
}
```

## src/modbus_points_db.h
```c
#ifndef MODBUS_POINTS_DB_H
#define MODBUS_POINTS_DB_H

#include <stdbool.h>
#include <stdint.h>

/* Holding Register 地址定义（FC03/FC06/FC16） */
#define MODBUS_POINT_HR_DEVICE_ID    0U
#define MODBUS_POINT_HR_THRESHOLD    1U
#define MODBUS_POINT_HR_RETRY_MS     2U
#define MODBUS_POINT_HR_USER_WORD    3U
#define MODBUS_POINT_HR_COUNT        4U

/* Coil 地址定义（FC01/FC05/FC15） */
#define MODBUS_POINT_COIL_ENABLE     0U
#define MODBUS_POINT_COIL_SAVE_EN    1U
#define MODBUS_POINT_COIL_COUNT      2U

/* 初始化 FlashDB KV 数据库 */
int modbus_points_db_init(void);

/* 读取/写入 Holding Register（底层映射为 FlashDB KV） */
int modbus_points_db_get_holding(uint16_t addr, uint16_t *value);
int modbus_points_db_set_holding(uint16_t addr, uint16_t value);

/* 读取/写入 Coil（底层映射为 FlashDB KV） */
int modbus_points_db_get_coil(uint16_t addr, bool *state);
int modbus_points_db_set_coil(uint16_t addr, bool state);

#endif /* MODBUS_POINTS_DB_H */
```

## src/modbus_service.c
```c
#include <zephyr/kernel.h>
#include <zephyr/modbus/modbus.h>
#include <zephyr/sys/util.h>
#include <zephyr/sys/printk.h>
#include <zephyr/sys/byteorder.h>
#include <zephyr/sys/crc.h>
#include <string.h>
#include <errno.h>

#include "modbus_service.h"
#include "modbus_points_db.h"
#include "usart_service.h"

/* 仅保留少量输入寄存器作为运行态只读信息 */
#define MB_INPUT_REG_NUM    4
#define MB_RAW_IFACE_NAME   "RAW_0"
#define MB_FRAME_MAX_LEN    CONFIG_MODBUS_BUFFER_SIZE
#define MB_POLL_BUF_LEN     64U
#define MB_FRAME_GAP_MS     2U
#define MB_ADU_PROTO_ID     0x0000U

static uint16_t input_reg[MB_INPUT_REG_NUM];
static int modbus_iface = -1;
static uint8_t mb_rx_frame[MB_FRAME_MAX_LEN];
static size_t mb_rx_len;
static int64_t mb_last_rx_ms;
static int64_t hb_last_ms;

/* Coil 读取：底层直接从持久化点位存储获取 */
static int coil_rd(uint16_t addr, bool *state)
{
	return modbus_points_db_get_coil(addr, state);
}

/* Coil 写入：写入后立即持久化到 flash 分区 */
static int coil_wr(uint16_t addr, bool state)
{
	return modbus_points_db_set_coil(addr, state);
}

/* Input Register 读取：当前采用内存态（不持久化） */
static int input_reg_rd(uint16_t addr, uint16_t *reg)
{
	if (addr >= MB_INPUT_REG_NUM) {
		return -ENOTSUP;
	}

	*reg = input_reg[addr];
	return 0;
}

/* Holding Register 读取：从持久化点位存储获取 */
static int holding_reg_rd(uint16_t addr, uint16_t *reg)
{
	return modbus_points_db_get_holding(addr, reg);
}

/* Holding Register 写入：更新后持久化 */
static int holding_reg_wr(uint16_t addr, uint16_t reg)
{
	return modbus_points_db_set_holding(addr, reg);
}

static int modbus_raw_tx_cb(const int iface, const struct modbus_adu *adu, void *user_data)
{
	uint8_t frame[MB_FRAME_MAX_LEN];
	uint16_t crc;
	size_t frame_len;
	int ret;

	ARG_UNUSED(iface);
	ARG_UNUSED(user_data);

	if (adu == NULL) {
		return -EINVAL;
	}

	if (adu->length > (MB_FRAME_MAX_LEN - 4U)) {
		return -EMSGSIZE;
	}

	frame[0] = adu->unit_id;
	frame[1] = adu->fc;
	if (adu->length > 0U) {
		memcpy(&frame[2], adu->data, adu->length);
	}

	crc = crc16_ansi(frame, adu->length + 2U);
	sys_put_le16(crc, &frame[2U + adu->length]);
	frame_len = adu->length + 4U;

	ret = rs485_write(frame, frame_len);
	if (ret != 0) {
		printk("rs485_write failed: %d\n", ret);
	}

	return ret;
}

/* Modbus Server 用户回调表 */
static struct modbus_user_callbacks mbs_cbs = {
	.coil_rd = coil_rd,
	.coil_wr = coil_wr,
	.input_reg_rd = input_reg_rd,
	.holding_reg_rd = holding_reg_rd,
	.holding_reg_wr = holding_reg_wr,
};

/* RAW 模式：协议栈仍使用标准 server 回调，串口由应用层自行管理 */
static struct modbus_iface_param server_param = {
	.mode = MODBUS_MODE_RAW,
	.server = {
		.user_cb = &mbs_cbs,
		.unit_id = 1,
	},
	.rawcb = {
		.raw_tx_cb = modbus_raw_tx_cb,
		.user_data = NULL,
	},
};

static void modbus_submit_frame(void)
{
	struct modbus_adu adu = { 0 };
	uint16_t rx_crc;
	uint16_t calc_crc;
	size_t payload_len;
	int err;

	if (mb_rx_len < 4U) {
		mb_rx_len = 0U;
		return;
	}

	rx_crc = sys_get_le16(&mb_rx_frame[mb_rx_len - 2U]);
	calc_crc = crc16_ansi(mb_rx_frame, mb_rx_len - 2U);
	if (rx_crc != calc_crc) {
		printk("Modbus RX CRC mismatch: rx=0x%04x calc=0x%04x len=%zu\n",
		       rx_crc, calc_crc, mb_rx_len);
		mb_rx_len = 0U;
		return;
	}

	payload_len = mb_rx_len - 4U;
	adu.proto_id = MB_ADU_PROTO_ID;
	adu.unit_id = mb_rx_frame[0];
	adu.fc = mb_rx_frame[1];
	adu.length = payload_len;
	adu.crc = rx_crc;
	if (payload_len > 0U) {
		memcpy(adu.data, &mb_rx_frame[2], payload_len);
	}

	err = modbus_raw_submit_rx(modbus_iface, &adu);
	if (err != 0) {
		printk("modbus_raw_submit_rx failed: %d\n", err);
	}

	mb_rx_len = 0U;
}

static void modbus_rx_poll(void)
{
	uint8_t tmp[MB_POLL_BUF_LEN];
	int rd;
	int64_t now;

	for (;;) {
		rd = rs485_read(tmp, sizeof(tmp), K_NO_WAIT);
		if (rd <= 0) {
			break;
		}

		if ((mb_rx_len + (size_t)rd) > sizeof(mb_rx_frame)) {
			printk("Modbus RX overflow, drop frame (len=%zu, add=%d)\n", mb_rx_len, rd);
			mb_rx_len = 0U;
		}

		if ((mb_rx_len + (size_t)rd) <= sizeof(mb_rx_frame)) {
			memcpy(&mb_rx_frame[mb_rx_len], tmp, (size_t)rd);
			mb_rx_len += (size_t)rd;
			mb_last_rx_ms = k_uptime_get();
		}
	}

	now = k_uptime_get();
	if (mb_rx_len >= 4U && (now - mb_last_rx_ms) >= MB_FRAME_GAP_MS) {
		modbus_submit_frame();
	}
}

int modbus_service_init(void)
{
	int err;

	/* RAW_0 为 Modbus RAW 接口名，由 CONFIG_MODBUS_NUMOF_RAW_ADU 提供 */
	modbus_iface = modbus_iface_get_by_name(MB_RAW_IFACE_NAME);
	if (modbus_iface < 0) {
		printk("Modbus iface lookup failed: %d\n", modbus_iface);
		return modbus_iface;
	}

	/* 初始化点位持久化数据（损坏时会自动恢复默认值） */
	err = modbus_points_db_init();
	if (err != 0) {
		printk("modbus_points_db_init failed: %d\n", err);
		return err;
	}

	err = rs485_init();
	if (err != 0) {
		printk("rs485_init failed: %d\n", err);
		return err;
	}

	/* input_reg[0] 作为心跳计数寄存器 */
	input_reg[0] = 0;
	mb_rx_len = 0U;
	mb_last_rx_ms = 0;
	hb_last_ms = k_uptime_get();

	/* 启动 Modbus RAW Server */
	err = modbus_init_server(modbus_iface, server_param);
	if (err != 0) {
		printk("modbus_init_server failed: %d\n", err);
		return err;
	}

	printk("Modbus RAW server ready on %s (iface=%d, unit_id=1)\n",
	       MB_RAW_IFACE_NAME, modbus_iface);
	return 0;
}

void modbus_service_tick(void)
{
	int64_t now = k_uptime_get();

	modbus_rx_poll();

	/* 每秒自增一次，用于 FC04 读取在线心跳值 */
	if ((now - hb_last_ms) >= 1000) {
		input_reg[0]++;
		hb_last_ms = now;
	}
}
```

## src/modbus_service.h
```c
#ifndef MODBUS_SERVICE_H
#define MODBUS_SERVICE_H

#include <stdint.h>

/* 初始化 Modbus RAW Server（协议处理 + 应用层 RS485 收发） */
int modbus_service_init(void);

/* 周期任务：轮询 RS485 输入并维护少量运行时寄存器（如心跳） */
void modbus_service_tick(void);

#endif /* MODBUS_SERVICE_H */
```

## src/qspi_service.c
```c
#include <zephyr/kernel.h>
#include <zephyr/device.h>
#include <zephyr/drivers/flash.h>
#include <string.h>
#include "qspi_service.h"

/* 使用板级 DTS 中定义的 qspi_flash 节点 */
#define QSPI_FLASH_NODE DT_NODELABEL(qspi_flash)

/* 旧测试模块参数：仅在起始 4KB 区域循环写入 */
#define QSPI_BASE_OFF    0u
#define QSPI_REGION_SIZE 4096u
#define RX_BUF_SIZE      64u

static const struct device *qspi_dev = DEVICE_DT_GET(QSPI_FLASH_NODE);

static uint32_t qspi_erase_size;
static uint32_t qspi_write_block;
static uint32_t qspi_write_off;

void qspi_service_dump(uint32_t off, size_t len)
{
	uint8_t buf[16];

	for (size_t i = 0; i < len; i += sizeof(buf)) {
		size_t chunk = len - i;
		if (chunk > sizeof(buf)) {
			chunk = sizeof(buf);
		}

		if (flash_read(qspi_dev, off + i, buf, chunk) != 0) {
			printk("QSPI read failed\n");
			return;
		}

		printk("0x%08x: ", (unsigned int)(off + i));
		for (size_t j = 0; j < chunk; j++) {
			printk("%02x ", buf[j]);
		}
		printk("\n");
	}
}

int qspi_service_init(void)
{
	const struct flash_parameters *params;
	struct flash_pages_info page;

	if (!device_is_ready(qspi_dev)) {
		printk("QSPI not ready\n");
		return -ENODEV;
	}

	/* 记录 flash 写对齐粒度 */
	params = flash_get_parameters(qspi_dev);
	qspi_write_block = params->write_block_size;

	/* 查询起始偏移所在页大小（作为擦除粒度） */
	if (flash_get_page_info_by_offs(qspi_dev, QSPI_BASE_OFF, &page) != 0) {
		return -EIO;
	}

	qspi_erase_size = page.size;
	qspi_write_off = QSPI_BASE_OFF;

	printk("QSPI init OK\n");
	return 0;
}

int qspi_service_erase(void)
{
	return flash_erase(qspi_dev, QSPI_BASE_OFF, qspi_erase_size);
}

int qspi_service_write(const uint8_t *data, size_t len)
{
	uint8_t tmp[RX_BUF_SIZE];
	size_t padded;

	memcpy(tmp, data, len);

	/* 按写块大小补齐 */
	padded = len;
	if (padded % qspi_write_block) {
		padded = ((padded + qspi_write_block - 1) / qspi_write_block) * qspi_write_block;
	}

	memset(&tmp[len], 0xFF, padded - len);

	/* 超出测试窗口则擦除回绕 */
	if ((qspi_write_off + padded) > (QSPI_BASE_OFF + QSPI_REGION_SIZE)) {
		qspi_service_erase();
		qspi_write_off = QSPI_BASE_OFF;
	}

	if (flash_write(qspi_dev, qspi_write_off, tmp, padded) != 0) {
		return -EIO;
	}

	qspi_write_off += padded;
	return 0;
}
```
